VERSION ""

NS_ :

BS_:

BU_:

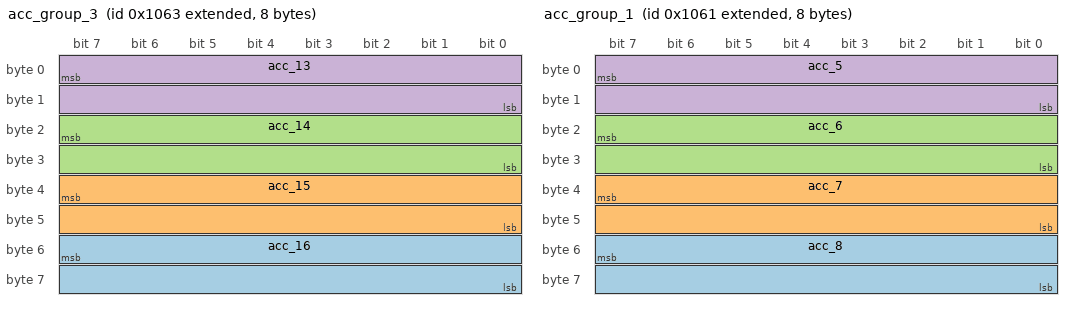
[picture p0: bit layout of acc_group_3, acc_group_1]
BO_ 2147487843 acc_group_3: 8 Vector__XXX
 SG_ acc_16 : 55|16@0+ (1,0) [0|5] "V" Vector__XXX
 SG_ acc_15 : 39|16@0+ (1,0) [0|5] "V" Vector__XXX
 SG_ acc_14 : 23|16@0+ (1,0) [0|5] "V" Vector__XXX
 SG_ acc_13 : 7|16@0+ (1,0) [0|5] "V" Vector__XXX

BO_ 2147487841 acc_group_1: 8 Vector__XXX
 SG_ acc_8 : 55|16@0+ (1,0) [0|5] "V" Vector__XXX
 SG_ acc_7 : 39|16@0+ (1,0) [0|5] "V" Vector__XXX
 SG_ acc_6 : 23|16@0+ (1,0) [0|5] "V" Vector__XXX
 SG_ acc_5 : 7|16@0+ (1,0) [0|5] "V" Vector__XXX

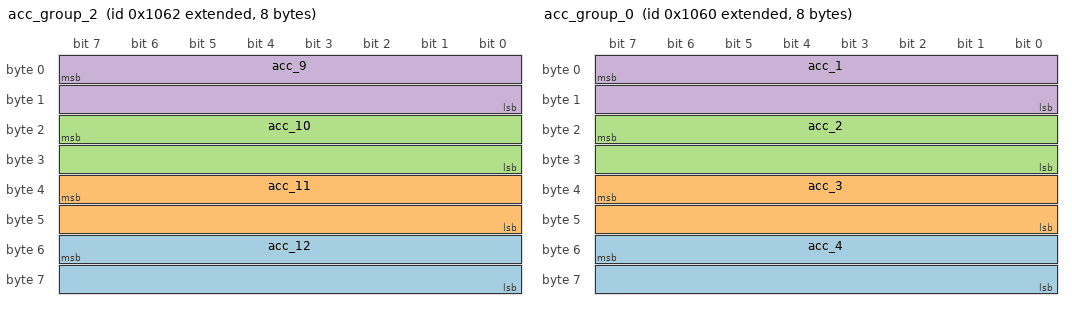
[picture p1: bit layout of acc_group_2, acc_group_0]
BO_ 2147487842 acc_group_2: 8 Vector__XXX
 SG_ acc_12 : 55|16@0+ (1,0) [0|5] "V" Vector__XXX
 SG_ acc_11 : 39|16@0+ (1,0) [0|5] "V" Vector__XXX
 SG_ acc_10 : 23|16@0+ (1,0) [0|5] "V" Vector__XXX
 SG_ acc_9 : 7|16@0+ (1,0) [0|5] "V" Vector__XXX

BO_ 2147487840 acc_group_0: 8 Vector__XXX
 SG_ acc_4 : 55|16@0+ (1,0) [0|5] "V" Vector__XXX
 SG_ acc_3 : 39|16@0+ (1,0) [0|5] "V" Vector__XXX
 SG_ acc_2 : 23|16@0+ (1,0) [0|5] "V" Vector__XXX
 SG_ acc_1 : 7|16@0+ (1,0) [0|5] "V" Vector__XXX

BO_ 2147487809 diagnostics: 2 Vector__XXX
 SG_ display_temp : 7|16@0- (1,0) [0|100] "°C" Vector__XXX

BO_ 1143 group46: 8 Vector__XXX
 SG_ cut_percentage : 23|16@0+ (1,0) [0|0] "%" Vector__XXX

BO_ 1129 group38: 8 Vector__XXX
 SG_ ecu_temperature : 7|16@0+ (1,0) [0|0] "K" Vector__XXX

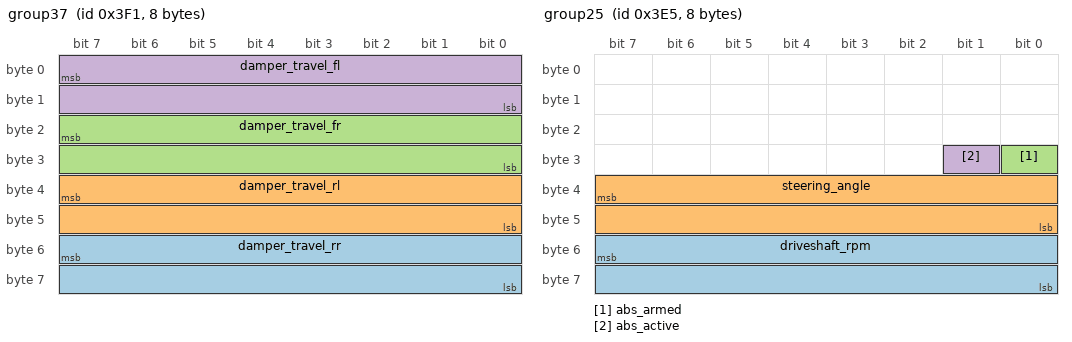
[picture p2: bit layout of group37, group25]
BO_ 1009 group37: 8 Vector__XXX
 SG_ damper_travel_rr : 55|16@0- (1,0) [0|0] "mm" Vector__XXX
 SG_ damper_travel_rl : 39|16@0- (1,0) [0|0] "mm" Vector__XXX
 SG_ damper_travel_fr : 23|16@0- (1,0) [0|0] "mm" Vector__XXX
 SG_ damper_travel_fl : 7|16@0- (1,0) [0|0] "mm" Vector__XXX

BO_ 1001 group29: 8 Vector__XXX
 SG_ target_lambda : 39|16@0+ (1,0) [0|0] "Lambda" Vector__XXX

BO_ 997 group25: 8 Vector__XXX
 SG_ driveshaft_rpm : 55|16@0+ (1,0) [0|0] "RPM" Vector__XXX
 SG_ steering_angle : 39|16@0- (1,0) [0|0] "deg" Vector__XXX
 SG_ abs_armed : 24|1@0+ (1,0) [0|0] "enum" Vector__XXX
 SG_ abs_active : 25|1@0+ (1,0) [0|0] "enum" Vector__XXX

BO_ 994 group22: 8 Vector__XXX
 SG_ fuel_level : 7|16@0+ (1,0) [0|0] "L" Vector__XXX

BO_ 881 group14: 8 Vector__XXX
 SG_ fuel_flow : 7|16@0+ (1,0) [0|0] "cc/min" Vector__XXX

BO_ 878 group11: 8 Vector__XXX
 SG_ ecu_lon_acc : 55|16@0- (1,0) [0|0] "m/s2" Vector__XXX
 SG_ engine_limit_act : 7|16@0+ (1,0) [0|0] "boolean" Vector__XXX

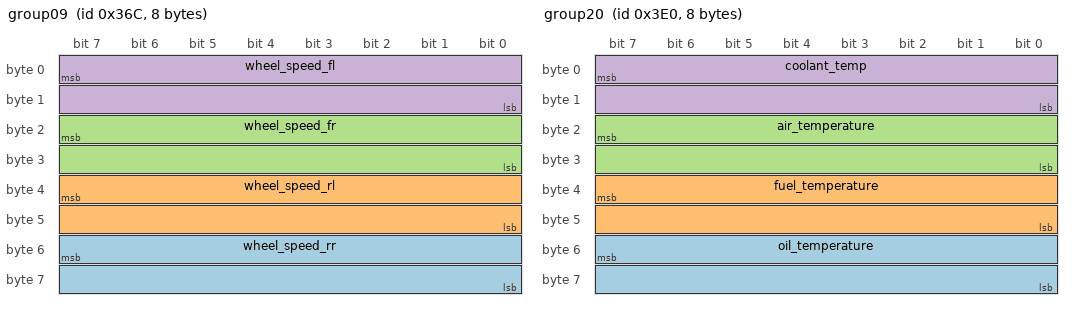
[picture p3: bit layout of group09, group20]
BO_ 876 group09: 8 Vector__XXX
 SG_ wheel_speed_rr : 55|16@0+ (1,0) [0|0] "km/h" Vector__XXX
 SG_ wheel_speed_rl : 39|16@0+ (1,0) [0|0] "km/h" Vector__XXX
 SG_ wheel_speed_fr : 23|16@0+ (1,0) [0|0] "km/h" Vector__XXX
 SG_ wheel_speed_fl : 7|16@0+ (1,0) [0|0] "km/h" Vector__XXX

BO_ 875 group08: 8 Vector__XXX
 SG_ ecu_lat_acc : 55|16@0- (1,0) [0|0] "m/s2" Vector__XXX
 SG_ brake_pres_front : 7|16@0+ (1,0) [0|0] "kPa" Vector__XXX

BO_ 867 group03: 8 Vector__XXX
 SG_ wheel_diff : 23|16@0- (1,0) [0|0] "km/h" Vector__XXX
 SG_ wheel_slip : 7|16@0- (1,0) [0|0] "km/h" Vector__XXX

BO_ 1142 group45: 8 Vector__XXX
 SG_ brake_pres_diff : 55|16@0- (1,0) [0|0] "kPa (Abs)" Vector__XXX
 SG_ brake_pres_rear : 7|16@0+ (1,0) [0|0] "kPa" Vector__XXX

BO_ 1779 group50: 8 Vector__XXX
 SG_ engine_prot_reas : 55|16@0+ (1,0) [0|0] "enum" Vector__XXX

BO_ 1140 group43: 8 Vector__XXX
 SG_ ecu_ver_acc : 7|16@0- (1,0) [0|0] "m/s2" Vector__XXX

BO_ 1139 group42: 8 Vector__XXX
 SG_ total_fuel_used : 7|32@0+ (1,0) [0|0] "cc" Vector__XXX

BO_ 1137 group40: 8 Vector__XXX
 SG_ apps : 23|16@0+ (1,0) [0|0] "%" Vector__XXX

BO_ 992 group20: 8 Vector__XXX
 SG_ oil_temperature : 55|16@0+ (1,0) [0|0] "K" Vector__XXX
 SG_ fuel_temperature : 39|16@0+ (1,0) [0|0] "K" Vector__XXX
 SG_ air_temperature : 23|16@0+ (1,0) [0|0] "K" Vector__XXX
 SG_ coolant_temp : 7|16@0+ (1,0) [0|0] "K" Vector__XXX

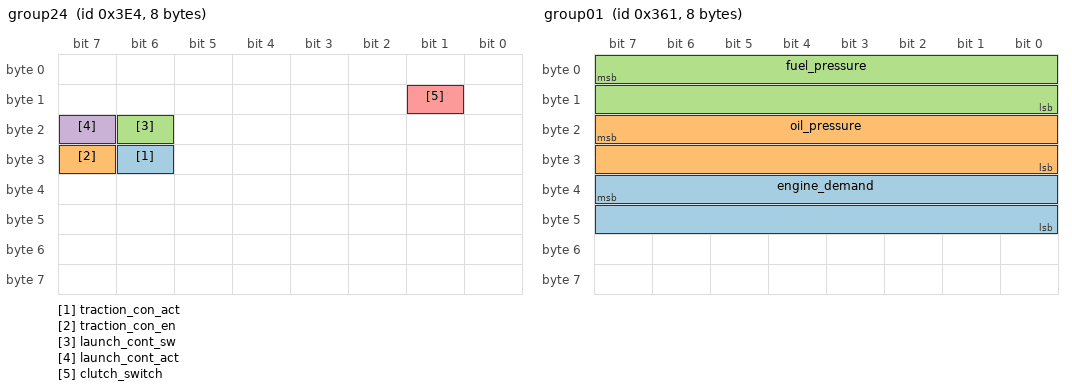
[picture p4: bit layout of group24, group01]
BO_ 996 group24: 8 Vector__XXX
 SG_ traction_con_act : 30|1@0+ (1,0) [0|0] "boolean" Vector__XXX
 SG_ traction_con_en : 31|1@0+ (1,0) [0|0] "boolean" Vector__XXX
 SG_ launch_cont_sw : 22|1@0+ (1,0) [0|0] "boolean" Vector__XXX
 SG_ launch_cont_act : 23|1@0+ (1,0) [0|0] "boolean" Vector__XXX
 SG_ clutch_switch : 9|1@0+ (1,0) [0|0] "boolean" Vector__XXX

BO_ 882 group15: 8 Vector__XXX
 SG_ barometric_pres : 55|16@0+ (1,0) [0|0] "kPa (Abs)" Vector__XXX
 SG_ battery_voltage : 7|16@0+ (1,0) [0|0] "V" Vector__XXX

BO_ 1136 group39: 8 Vector__XXX
 SG_ gear : 63|8@0- (1,0) [0|0] "enum" Vector__XXX
 SG_ wideband_overall : 7|16@0+ (1,0) [0|0] "Lambda" Vector__XXX

BO_ 880 group13: 8 Vector__XXX
 SG_ vehicle_speed : 7|16@0+ (1,0) [0|0] "km/h" Vector__XXX

BO_ 865 group01: 8 Vector__XXX
 SG_ engine_demand : 39|16@0+ (1,0) [0|0] "%" Vector__XXX
 SG_ oil_pressure : 23|16@0+ (1,0) [0|0] "kPa" Vector__XXX
 SG_ fuel_pressure : 7|16@0+ (1,0) [0|0] "kPa" Vector__XXX

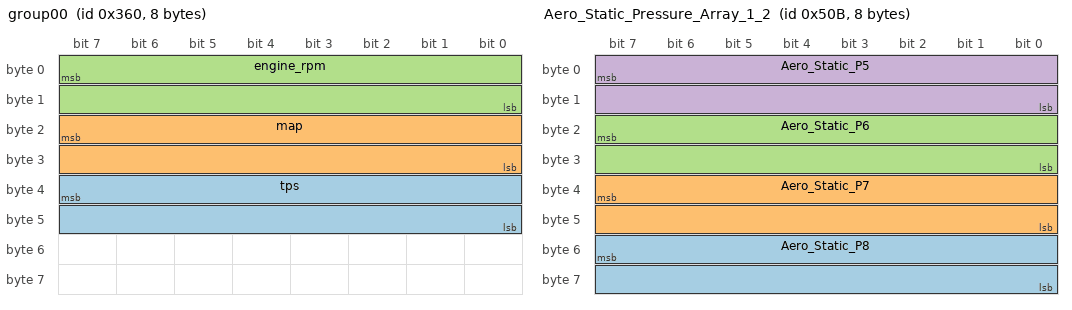
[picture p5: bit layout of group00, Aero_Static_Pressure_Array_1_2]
BO_ 864 group00: 8 Vector__XXX
 SG_ tps : 39|16@0+ (1,0) [0|0] "%" Vector__XXX
 SG_ map : 23|16@0+ (1,0) [0|0] "kPa (Abs)" Vector__XXX
 SG_ engine_rpm : 7|16@0+ (1,0) [0|0] "RPM" Vector__XXX

BO_ 1292 Aero_Static_Pressure_Array_1_3: 4 Vector__XXX
 SG_ P_Scanner_Temp : 23|16@0- (1,0) [-327.68|327.67] "C" Vector__XXX
 SG_ Aero_Static_REF : 7|16@0- (1,0) [-327.68|327.67] "mbar" Vector__XXX

BO_ 1291 Aero_Static_Pressure_Array_1_2: 8 Vector__XXX
 SG_ Aero_Static_P8 : 55|16@0- (1,0) [-327.68|327.67] "mbar" Vector__XXX
 SG_ Aero_Static_P7 : 39|16@0- (1,0) [-327.68|327.67] "mbar" Vector__XXX
 SG_ Aero_Static_P6 : 23|16@0- (1,0) [-327.68|327.67] "mbar" Vector__XXX
 SG_ Aero_Static_P5 : 7|16@0- (1,0) [-327.68|327.67] "mbar" Vector__XXX

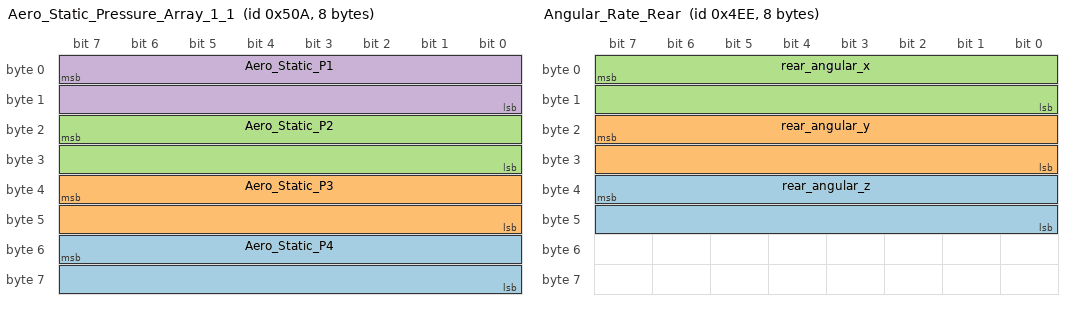
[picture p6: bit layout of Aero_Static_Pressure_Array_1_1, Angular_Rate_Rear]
BO_ 1290 Aero_Static_Pressure_Array_1_1: 8 Vector__XXX
 SG_ Aero_Static_P4 : 55|16@0- (1,0) [-327.68|327.67] "mbar" Vector__XXX
 SG_ Aero_Static_P3 : 39|16@0- (1,0) [-327.68|327.67] "mbar" Vector__XXX
 SG_ Aero_Static_P2 : 23|16@0- (1,0) [-327.68|327.67] "mbar" Vector__XXX
 SG_ Aero_Static_P1 : 7|16@0- (1,0) [-327.68|327.67] "mbar" Vector__XXX

BO_ 1262 Angular_Rate_Rear: 8 Vector__XXX
 SG_ rear_angular_z : 39|16@0- (1,0) [-3276.8|3276.7] "deg/sec" Vector__XXX
 SG_ rear_angular_y : 23|16@0- (1,0) [-3276.8|3276.7] "deg/sec" Vector__XXX
 SG_ rear_angular_x : 7|16@0- (1,0) [-3276.8|3276.7] "deg/sec" Vector__XXX

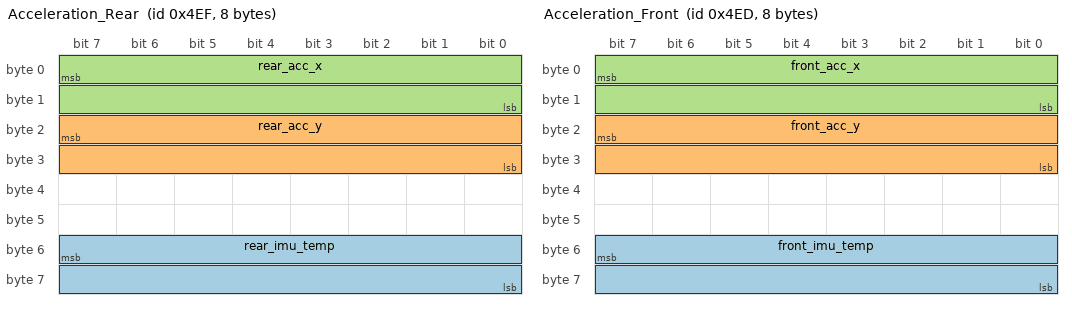
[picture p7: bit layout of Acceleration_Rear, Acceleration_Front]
BO_ 1263 Acceleration_Rear: 8 Vector__XXX
 SG_ rear_imu_temp : 55|16@0- (1,0) [-32768|32767] "C" Vector__XXX
 SG_ rear_acc_y : 23|16@0- (1,0) [-327.68|327.67] "g" Vector__XXX
 SG_ rear_acc_x : 7|16@0- (1,0) [-327.68|327.67] "g" Vector__XXX

BO_ 1261 Acceleration_Front: 8 Vector__XXX
 SG_ front_imu_temp : 55|16@0- (1,0) [-32768|32767] "C" Vector__XXX
 SG_ front_acc_y : 23|16@0- (1,0) [-327.68|327.67] "g" Vector__XXX
 SG_ front_acc_x : 7|16@0- (1,0) [-327.68|327.67] "g" Vector__XXX

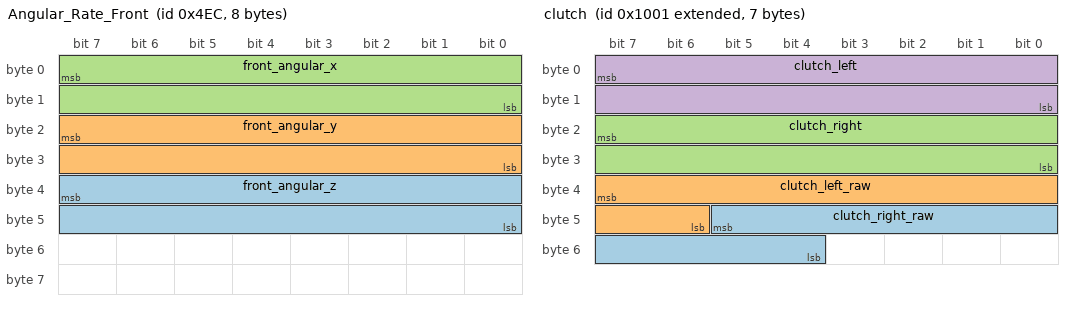
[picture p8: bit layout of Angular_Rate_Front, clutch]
BO_ 1260 Angular_Rate_Front: 8 Vector__XXX
 SG_ front_angular_z : 39|16@0- (1,0) [-3276.8|3276.7] "deg/sec" Vector__XXX
 SG_ front_angular_y : 23|16@0- (1,0) [-3276.8|3276.7] "deg/sec" Vector__XXX
 SG_ front_angular_x : 7|16@0- (1,0) [-3276.8|3276.7] "deg/sec" Vector__XXX

BO_ 2147487745 clutch: 7 Vector__XXX
 SG_ clutch_right_raw : 45|10@0+ (1,0) [0|0] "" Vector__XXX
 SG_ clutch_left_raw : 39|10@0+ (1,0) [0|0] "" Vector__XXX
 SG_ clutch_right : 23|16@0+ (1,0) [0|100] "%" Vector__XXX
 SG_ clutch_left : 7|16@0+ (1,0) [0|100] "%" Vector__XXX

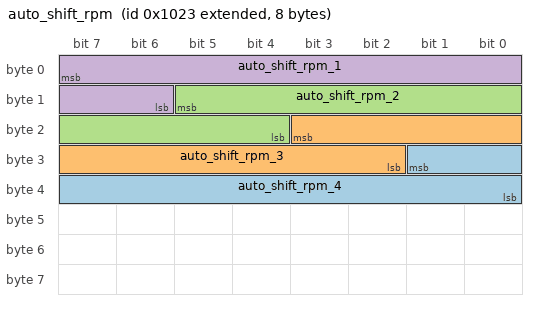
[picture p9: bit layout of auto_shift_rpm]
BO_ 2147487779 auto_shift_rpm: 8 Vector__XXX
 SG_ auto_shift_rpm_4 : 25|10@0+ (1,0) [10000|22276] "RPM" Vector__XXX
 SG_ auto_shift_rpm_3 : 19|10@0+ (1,0) [10000|22276] "RPM" Vector__XXX
 SG_ auto_shift_rpm_2 : 13|10@0+ (1,0) [10000|22276] "RPM" Vector__XXX
 SG_ auto_shift_rpm_1 : 7|10@0+ (1,0) [10000|22276] "RPM" Vector__XXX

BO_ 2147487776 servo: 5 Vector__XXX
 SG_ servo_pot : 27|12@0+ (1,0) [0|0] "v" Vector__XXX
 SG_ servo_position : 23|12@0+ (1,0) [0|0] "us" Vector__XXX

BO_ 2147487777 settings: 8 Vector__XXX
 SG_ auto_shift : 47|1@0+ (1,0) [0|0] "boolean" Vector__XXX

CM_ SG_ 1142 brake_pres_diff "Front-Rear";
CM_ SG_ 1779 engine_prot_reas "This value is hexadecimal, and represents the OBDII DTC. 
The upper 2 bits determine which letter it is (0b00 = P, 0b01 = B, 0b10 = C, 0b11 = U). The remaining 14 bits, when viewed as hexadecimal are the number part of the code. 

";
BA_DEF_ BO_  "GenMsgCycleTime" INT 0 65535;
BA_DEF_DEF_  "GenMsgCycleTime" 0;
BA_ "GenMsgCycleTime" BO_ 2147487843 4;
BA_ "GenMsgCycleTime" BO_ 2147487841 4;
BA_ "GenMsgCycleTime" BO_ 2147487842 4;
BA_ "GenMsgCycleTime" BO_ 2147487840 4;
BA_ "GenMsgCycleTime" BO_ 1143 100;
BA_ "GenMsgCycleTime" BO_ 1129 200;
BA_ "GenMsgCycleTime" BO_ 1009 20;
BA_ "GenMsgCycleTime" BO_ 1001 50;
BA_ "GenMsgCycleTime" BO_ 997 20;
BA_ "GenMsgCycleTime" BO_ 994 200;
BA_ "GenMsgCycleTime" BO_ 881 100;
BA_ "GenMsgCycleTime" BO_ 878 50;
BA_ "GenMsgCycleTime" BO_ 876 50;
BA_ "GenMsgCycleTime" BO_ 875 50;
BA_ "GenMsgCycleTime" BO_ 867 50;
BA_ "GenMsgCycleTime" BO_ 1142 50;
BA_ "GenMsgCycleTime" BO_ 1779 200;
BA_ "GenMsgCycleTime" BO_ 1140 50;
BA_ "GenMsgCycleTime" BO_ 1139 100;
BA_ "GenMsgCycleTime" BO_ 1137 20;
BA_ "GenMsgCycleTime" BO_ 992 200;
BA_ "GenMsgCycleTime" BO_ 996 200;
BA_ "GenMsgCycleTime" BO_ 882 100;
BA_ "GenMsgCycleTime" BO_ 1136 50;
BA_ "GenMsgCycleTime" BO_ 880 50;
BA_ "GenMsgCycleTime" BO_ 865 20;
BA_ "GenMsgCycleTime" BO_ 864 20;
BA_ "GenMsgCycleTime" BO_ 1292 4;
BA_ "GenMsgCycleTime" BO_ 1291 4;
BA_ "GenMsgCycleTime" BO_ 1290 4;
BA_ "GenMsgCycleTime" BO_ 1262 20;
BA_ "GenMsgCycleTime" BO_ 1263 20;
BA_ "GenMsgCycleTime" BO_ 1261 20;
BA_ "GenMsgCycleTime" BO_ 1260 20;
BA_ "GenMsgCycleTime" BO_ 2147487745 10;
BA_ "GenMsgCycleTime" BO_ 2147487779 1000;
BA_ "GenMsgCycleTime" BO_ 2147487776 20;
BA_ "GenMsgCycleTime" BO_ 2147487777 200;
